# PMBUS register map
Vendor: Texas Instruments
Peripheral module from a debugger description file (folder ucd3138128A).
Registers are 32-bit, access not given, no defined reset value unless marked. A register's access mark holds for its fields unless they carry their own. Offsets are as the file gives them; lines under a group give offsets from that group; [hi:lo] are bit positions; {n}, {i} and the like mark numbered series; 'fields as' and 'values as' point back to an identical list; <NAME> marks a mode.

## PMBUS
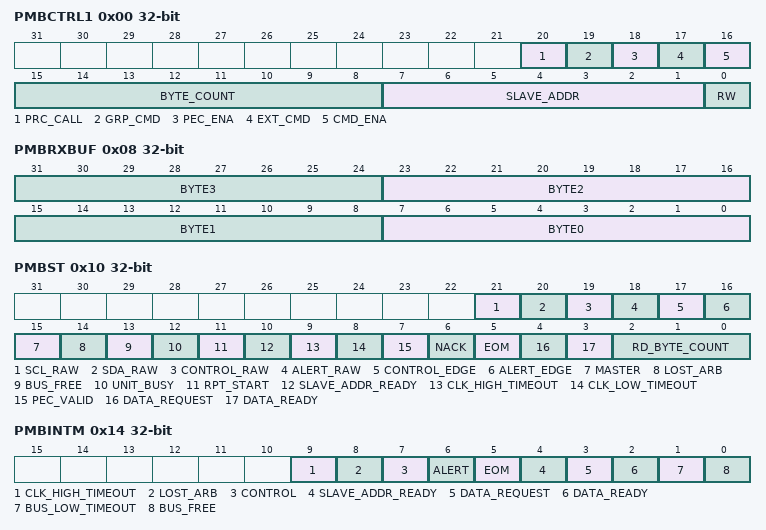
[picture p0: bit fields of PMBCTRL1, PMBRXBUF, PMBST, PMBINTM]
0x00 PMBCTRL1 — PMBus Control Register 1
  [20] PRC_CALL rw — Process call message enable
  [19] GRP_CMD rw — Group command message enable
  [18] PEC_ENA rw — PEC byte enable
  [17] EXT_CMD rw — Extended command enable
  [16] CMD_ENA rw — Command word enable
  [15:8] BYTE_COUNT rw
  [7:1] SLAVE_ADDR rw — Slave address
  [0] RW rw — Read/write indicator
0x04 PMBTXBUF rw — PMBus Transmit Data Buffer
  [31:0] ALL — All the bits
0x08 PMBRXBUF ro — PMBus Receive Data Buffer
  [8n+7:8n] BYTE{n} (n=0..3)
0x0C PMBACK — PMBus Acknowledge Register
  [0] ACK rw — Acknowledge enable
0x10 PMBST — PMBus Status Register
  [21] SCL_RAW ro — PMBus Clock Status
  [20] SDA_RAW ro — PMBus Data Status
  [19] CONTROL_RAW ro — Control Raw Status
  [18] ALERT_RAW ro — Alert Raw Status
  [17] CONTROL_EDGE ro — Control Signal Edge Detected
  [16] ALERT_EDGE ro — Alert signal detected flag
  [15] MASTER ro — Master/Slave mode flag
  [14] LOST_ARB ro — Lost arbitration flag
  [13] BUS_FREE ro — Bus free flag
  [12] UNIT_BUSY ro — Unit busy flag
  [11] RPT_START ro — Repeated start condition flag
  [10] SLAVE_ADDR_READY ro — Slave address ready flag
  [9] CLK_HIGH_TIMEOUT ro — Clock high timeout flag
  [8] CLK_LOW_TIMEOUT ro — Clock low timeout flag
  [7] PEC_VALID ro — PEC valid flag
  [6] NACK ro — NACK condition received flag
  [5] EOM ro — End of message flag
  [4] DATA_REQUEST ro — Data request flag
  [3] DATA_READY ro — Data ready flag
  [2:0] RD_BYTE_COUNT ro — Read byte count
0x14 PMBINTM — PMBus Interrupt Mask Register
  [9] CLK_HIGH_TIMEOUT rw — Clock High Detection Interrupt mask
  [8] LOST_ARB rw — Lost arbitration interrupt mask
  [7] CONTROL rw — Remote module control asserted interrupt mask
  [6] ALERT rw — Alert signal detected interrupt mask
  [5] EOM rw — End of message interrupt mask
  [4] SLAVE_ADDR_READY rw — Slave address ready interrupt mask
  [3] DATA_REQUEST rw — Data request interrupt mask
  [2] DATA_READY rw — Data ready interrupt mask
  [1] BUS_LOW_TIMEOUT rw — Bus low timeout interrupt mask
  [0] BUS_FREE rw — Bus free interrupt mask
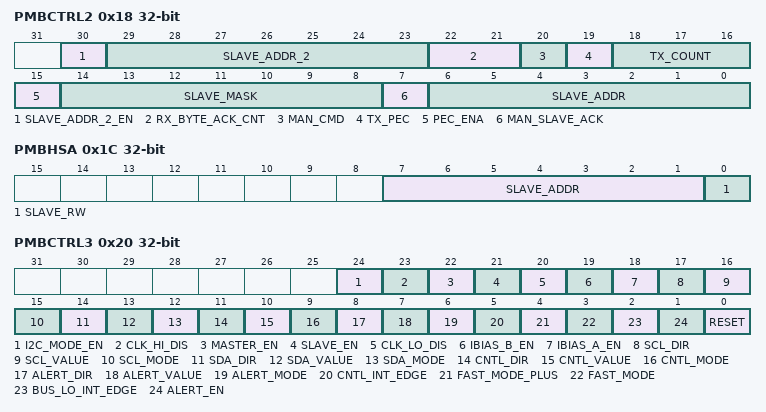
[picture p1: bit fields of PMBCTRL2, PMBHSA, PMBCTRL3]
0x18 PMBCTRL2 — PMBus Control Register 2
  [30] SLAVE_ADDR_2_EN rw — Slave address 2 enable
  [29:23] SLAVE_ADDR_2 rw — Slave address 2 value
  [22:21] RX_BYTE_ACK_CNT rw — Num bytes to auto acknowledge in slave mode
  [20] MAN_CMD rw — Manual command acknowledge mode
  [19] TX_PEC rw — Transmited PEC flag
  [18:16] TX_COUNT rw — Transmit byte count
  [15] PEC_ENA rw — Enable PEC processing
  [14:8] SLAVE_MASK rw
  [7] MAN_SLAVE_ACK rw — Manual slave acknowledge mode enable
  [6:0] SLAVE_ADDR rw — Slave address
0x1C PMBHSA — PMBus Hold Slave Address Register
  [7:1] SLAVE_ADDR ro — Stored address acknowledged by slave
  [0] SLAVE_RW ro — Stored R/W bit from slave acknowledge
0x20 PMBCTRL3 — PMBus Control Register 3
  [24] I2C_MODE_EN rw — I2C Mode Enable
  [23] CLK_HI_DIS rw — Clock High Timeout Disable
  [22] MASTER_EN rw — Master Mode Enable
  [21] SLAVE_EN rw — Slave Mode Enable
  [20] CLK_LO_DIS rw — Clock Low Timeout Disable
  [19] IBIAS_B_EN rw — IBias B enable
  [18] IBIAS_A_EN rw — IBias A enable
  [17] SCL_DIR rw — Clock Pin GPIO Direction
  [16] SCL_VALUE rw — Clock Pin GPIO Value
  [15] SCL_MODE rw — Clock Pin GPIO Mode
  [14] SDA_DIR rw — Clock Pin GPIO Direction
  [13] SDA_VALUE rw — Clock Pin GPIO Value
  [12] SDA_MODE rw — Clock Pin GPIO Mode
  [11] CNTL_DIR rw — Direction of control pins in GPIO mode
  [10] CNTL_VALUE rw — Output value of control pins in GPIO mode
  [9] CNTL_MODE rw — Configures mode of control pins
  [8] ALERT_DIR rw — Alert Pin GPIO Direction
  [7] ALERT_VALUE rw — Value of Alert pin in GPIO mode
  [6] ALERT_MODE rw — Configures mode of Alert pin
  [5] CNTL_INT_EDGE rw — Control interrupt edge select
  [4] FAST_MODE_PLUS rw — Fast mode plus enable
  [3] FAST_MODE rw — Fast mode enable
  [2] BUS_LO_INT_EDGE rw — Bus low timeout interrupt edge select
  [1] ALERT_EN rw — Alert enable
  [0] RESET rw — PMBus Master reset
